AUTOSAR XML (schema 4-3-0)
package /ComponentTypes
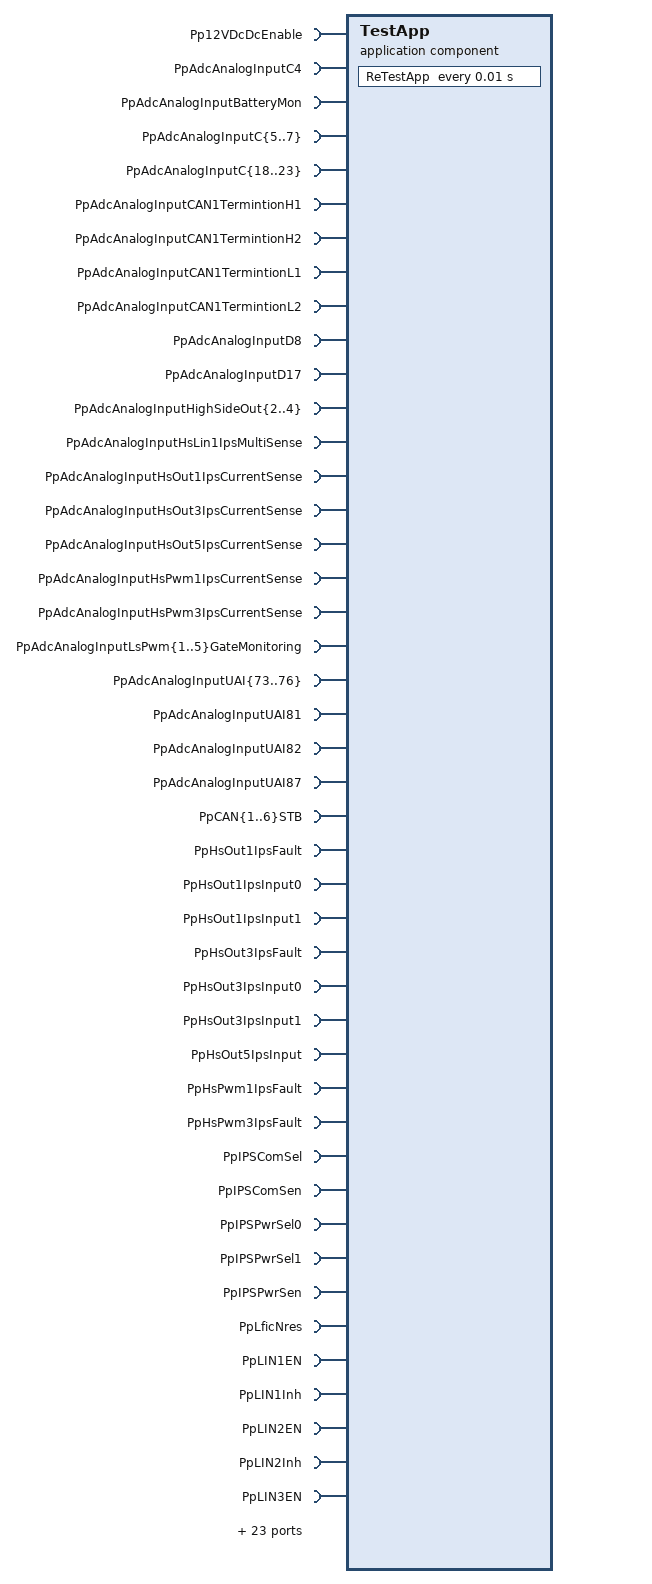
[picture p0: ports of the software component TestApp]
  application sw component type TestApp
    92 x require port:
      Pp12VDcDcEnable: required-com-specs=[]
      PpAdcAnalogInputC4
      PpAdcAnalogInputBatteryMon
      PpAdcAnalogInputC{5..7}
      PpAdcAnalogInputC{18..23}
      PpAdcAnalogInputCAN1TermintionH1
      PpAdcAnalogInputCAN1TermintionH2
      PpAdcAnalogInputCAN1TermintionL1
      PpAdcAnalogInputCAN1TermintionL2
      PpAdcAnalogInputD8
      PpAdcAnalogInputD17
      PpAdcAnalogInputHighSideOut{2..4}
      PpAdcAnalogInputHsLin1IpsMultiSense
      PpAdcAnalogInputHsOut1IpsCurrentSense
      PpAdcAnalogInputHsOut3IpsCurrentSense
      PpAdcAnalogInputHsOut5IpsCurrentSense
      PpAdcAnalogInputHsPwm1IpsCurrentSense
      PpAdcAnalogInputHsPwm3IpsCurrentSense
      PpAdcAnalogInputLsPwm{1..5}GateMonitoring
      PpAdcAnalogInputUAI{73..76}
      PpAdcAnalogInputUAI81
      PpAdcAnalogInputUAI82
      PpAdcAnalogInputUAI87
      PpCAN{1..6}STB: required-com-specs=[]
      PpHsOut1IpsFault: required-com-specs=[]
      PpHsOut1IpsInput0: required-com-specs=[]
      PpHsOut1IpsInput1: required-com-specs=[]
      PpHsOut3IpsFault: required-com-specs=[]
      PpHsOut3IpsInput0: required-com-specs=[]
      PpHsOut3IpsInput1: required-com-specs=[]
      PpHsOut5IpsInput: required-com-specs=[]
      PpHsPwm1IpsFault: required-com-specs=[]
      PpHsPwm3IpsFault: required-com-specs=[]
      PpIPSComSel: required-com-specs=[]
      PpIPSComSen: required-com-specs=[]
      PpIPSPwrSel0: required-com-specs=[]
      PpIPSPwrSel1: required-com-specs=[]
      PpIPSPwrSen: required-com-specs=[]
      PpLficNres: required-com-specs=[]
      PpLIN1EN: required-com-specs=[]
      PpLIN1Inh: required-com-specs=[]
      PpLIN2EN: required-com-specs=[]
      PpLIN2Inh: required-com-specs=[]
      PpLIN3EN: required-com-specs=[]
      PpLIN3Inh: required-com-specs=[]
      PpLIN4EN: required-com-specs=[]
      PpLIN4Inh: required-com-specs=[]
      PpLIN5EN: required-com-specs=[]
      PpLIN5Inh: required-com-specs=[]
      PpLIN6EN: required-com-specs=[]
      PpLIN6Inh: required-com-specs=[]
      PpLINPwrIpsFaultRst: required-com-specs=[]
      PpLINPwrIpsIn0: required-com-specs=[]
      PpLINPwrIpsIn1: required-com-specs=[]
      PpLINSecurityEN: required-com-specs=[]
      PpLINSecurityInh: required-com-specs=[]
      PpLivingPopUpCtrl: required-com-specs=[]
      PpParkedPopUpCtrl: required-com-specs=[]
      PpPwmHsPwm1IpsIn0
      PpPwmHsPwm1IpsIn1
      PpPwmHsPwm3IpsIn0
      PpPwmHsPwm3IpsIn1
      PpPwmLsPwm{1..5}Gate
      PpPwmRegWdtOut
      PpRegRst: required-com-specs=[]
      PpRficNres: required-com-specs=[]
      PpRficRed: required-com-specs=[]
    behavior TestApp_InternalBehavior
      timing event TMT_ReTestApp: start-on-event=ReTestApp, period=0.01
      runnable ReTestApp
        136 x sync call:
          SC_Pp12VDcDcEnable_DioRead: operation=Pp12VDcDcEnable
          SC_Pp12VDcDcEnable_DioWrite: operation=Pp12VDcDcEnable
          SC_PpAdcAnalogInputBatteryMon_AdcRead: operation=PpAdcAnalogInputBatteryMon
          SC_PpAdcAnalogInputC{18..23}_AdcRead: operation=PpAdcAnalogInputC{18..23}
          SC_PpAdcAnalogInputC{4..7}_AdcRead: operation=PpAdcAnalogInputC{4..7}
          SC_PpAdcAnalogInputCAN1TermintionH1_AdcRead: operation=PpAdcAnalogInputCAN1TermintionH1
          SC_PpAdcAnalogInputCAN1TermintionH2_AdcRead: operation=PpAdcAnalogInputCAN1TermintionH2
          SC_PpAdcAnalogInputCAN1TermintionL1_AdcRead: operation=PpAdcAnalogInputCAN1TermintionL1
          SC_PpAdcAnalogInputCAN1TermintionL2_AdcRead: operation=PpAdcAnalogInputCAN1TermintionL2
          SC_PpAdcAnalogInputD17_AdcRead: operation=PpAdcAnalogInputD17
          SC_PpAdcAnalogInputD8_AdcRead: operation=PpAdcAnalogInputD8
          SC_PpAdcAnalogInputHighSideOut{2..4}_AdcRead: operation=PpAdcAnalogInputHighSideOut{2..4}
          SC_PpAdcAnalogInputHsLin1IpsMultiSense_AdcRead: operation=PpAdcAnalogInputHsLin1IpsMultiSense
          SC_PpAdcAnalogInputHsOut1IpsCurrentSense_AdcRead: operation=PpAdcAnalogInputHsOut1IpsCurrentSense
          SC_PpAdcAnalogInputHsOut3IpsCurrentSense_AdcRead: operation=PpAdcAnalogInputHsOut3IpsCurrentSense
          SC_PpAdcAnalogInputHsOut5IpsCurrentSense_AdcRead: operation=PpAdcAnalogInputHsOut5IpsCurrentSense
          SC_PpAdcAnalogInputHsPwm1IpsCurrentSense_AdcRead: operation=PpAdcAnalogInputHsPwm1IpsCurrentSense
          SC_PpAdcAnalogInputHsPwm3IpsCurrentSense_AdcRead: operation=PpAdcAnalogInputHsPwm3IpsCurrentSense
          SC_PpAdcAnalogInputLsPwm{1..5}GateMonitoring_AdcRead: operation=PpAdcAnalogInputLsPwm{1..5}GateMonitoring
          SC_PpAdcAnalogInputUAI{73..76}_AdcRead: operation=PpAdcAnalogInputUAI{73..76}
          SC_PpAdcAnalogInputUAI81_AdcRead: operation=PpAdcAnalogInputUAI81
          SC_PpAdcAnalogInputUAI82_AdcRead: operation=PpAdcAnalogInputUAI82
          SC_PpAdcAnalogInputUAI87_AdcRead: operation=PpAdcAnalogInputUAI87
          SC_PpCAN1STB_DioRead: operation=PpCAN1STB
          SC_PpCAN1STB_DioWrite: operation=PpCAN1STB
          SC_PpCAN2STB_DioRead: operation=PpCAN2STB
          SC_PpCAN2STB_DioWrite: operation=PpCAN2STB
          SC_PpCAN3STB_DioRead: operation=PpCAN3STB
          SC_PpCAN3STB_DioWrite: operation=PpCAN3STB
          SC_PpCAN4STB_DioRead: operation=PpCAN4STB
          SC_PpCAN4STB_DioWrite: operation=PpCAN4STB
          SC_PpCAN5STB_DioRead: operation=PpCAN5STB
          SC_PpCAN5STB_DioWrite: operation=PpCAN5STB
          SC_PpCAN6STB_DioRead: operation=PpCAN6STB
          SC_PpCAN6STB_DioWrite: operation=PpCAN6STB
          SC_PpHsOut1IpsFault_DioRead: operation=PpHsOut1IpsFault
          SC_PpHsOut1IpsFault_DioWrite: operation=PpHsOut1IpsFault
          SC_PpHsOut1IpsInput0_DioRead: operation=PpHsOut1IpsInput0
          SC_PpHsOut1IpsInput0_DioWrite: operation=PpHsOut1IpsInput0
          SC_PpHsOut1IpsInput1_DioRead: operation=PpHsOut1IpsInput1
          SC_PpHsOut1IpsInput1_DioWrite: operation=PpHsOut1IpsInput1
          SC_PpHsOut3IpsFault_DioRead: operation=PpHsOut3IpsFault
          SC_PpHsOut3IpsFault_DioWrite: operation=PpHsOut3IpsFault
          SC_PpHsOut3IpsInput0_DioRead: operation=PpHsOut3IpsInput0
          SC_PpHsOut3IpsInput0_DioWrite: operation=PpHsOut3IpsInput0
          SC_PpHsOut3IpsInput1_DioRead: operation=PpHsOut3IpsInput1
          SC_PpHsOut3IpsInput1_DioWrite: operation=PpHsOut3IpsInput1
          SC_PpHsOut5IpsInput_DioRead: operation=PpHsOut5IpsInput
          SC_PpHsOut5IpsInput_DioWrite: operation=PpHsOut5IpsInput
          SC_PpHsPwm1IpsFault_DioRead: operation=PpHsPwm1IpsFault
          SC_PpHsPwm1IpsFault_DioWrite: operation=PpHsPwm1IpsFault
          SC_PpHsPwm3IpsFault_DioRead: operation=PpHsPwm3IpsFault
          SC_PpHsPwm3IpsFault_DioWrite: operation=PpHsPwm3IpsFault
          SC_PpIPSComSel_DioRead: operation=PpIPSComSel
          SC_PpIPSComSel_DioWrite: operation=PpIPSComSel
          SC_PpIPSComSen_DioRead: operation=PpIPSComSen
          SC_PpIPSComSen_DioWrite: operation=PpIPSComSen
          SC_PpIPSPwrSel0_DioRead: operation=PpIPSPwrSel0
          SC_PpIPSPwrSel0_DioWrite: operation=PpIPSPwrSel0
          SC_PpIPSPwrSel1_DioRead: operation=PpIPSPwrSel1
          SC_PpIPSPwrSel1_DioWrite: operation=PpIPSPwrSel1
          SC_PpIPSPwrSen_DioRead: operation=PpIPSPwrSen
          SC_PpIPSPwrSen_DioWrite: operation=PpIPSPwrSen
          SC_PpLIN1EN_DioRead: operation=PpLIN1EN
          SC_PpLIN1EN_DioWrite: operation=PpLIN1EN
          SC_PpLIN1Inh_DioRead: operation=PpLIN1Inh
          SC_PpLIN1Inh_DioWrite: operation=PpLIN1Inh
          SC_PpLIN2EN_DioRead: operation=PpLIN2EN
          SC_PpLIN2EN_DioWrite: operation=PpLIN2EN
          SC_PpLIN2Inh_DioRead: operation=PpLIN2Inh
          SC_PpLIN2Inh_DioWrite: operation=PpLIN2Inh
          SC_PpLIN3EN_DioRead: operation=PpLIN3EN
          SC_PpLIN3EN_DioWrite: operation=PpLIN3EN
          SC_PpLIN3Inh_DioRead: operation=PpLIN3Inh
          SC_PpLIN3Inh_DioWrite: operation=PpLIN3Inh
          SC_PpLIN4EN_DioRead: operation=PpLIN4EN
          SC_PpLIN4EN_DioWrite: operation=PpLIN4EN
          SC_PpLIN4Inh_DioRead: operation=PpLIN4Inh
          SC_PpLIN4Inh_DioWrite: operation=PpLIN4Inh
          SC_PpLIN5EN_DioRead: operation=PpLIN5EN
          SC_PpLIN5EN_DioWrite: operation=PpLIN5EN
          SC_PpLIN5Inh_DioRead: operation=PpLIN5Inh
          SC_PpLIN5Inh_DioWrite: operation=PpLIN5Inh
          SC_PpLIN6EN_DioRead: operation=PpLIN6EN
          SC_PpLIN6EN_DioWrite: operation=PpLIN6EN
          SC_PpLIN6Inh_DioRead: operation=PpLIN6Inh
          SC_PpLIN6Inh_DioWrite: operation=PpLIN6Inh
          SC_PpLINPwrIpsFaultRst_DioRead: operation=PpLINPwrIpsFaultRst
          SC_PpLINPwrIpsFaultRst_DioWrite: operation=PpLINPwrIpsFaultRst
          SC_PpLINPwrIpsIn0_DioRead: operation=PpLINPwrIpsIn0
          SC_PpLINPwrIpsIn0_DioWrite: operation=PpLINPwrIpsIn0
          SC_PpLINPwrIpsIn1_DioRead: operation=PpLINPwrIpsIn1
          SC_PpLINPwrIpsIn1_DioWrite: operation=PpLINPwrIpsIn1
          SC_PpLINSecurityEN_DioRead: operation=PpLINSecurityEN
          SC_PpLINSecurityEN_DioWrite: operation=PpLINSecurityEN
          SC_PpLINSecurityInh_DioRead: operation=PpLINSecurityInh
          SC_PpLINSecurityInh_DioWrite: operation=PpLINSecurityInh
          SC_PpLficNres_DioRead: operation=PpLficNres
          SC_PpLficNres_DioWrite: operation=PpLficNres
          SC_PpLivingPopUpCtrl_DioRead: operation=PpLivingPopUpCtrl
          SC_PpLivingPopUpCtrl_DioWrite: operation=PpLivingPopUpCtrl
          SC_PpParkedPopUpCtrl_DioRead: operation=PpParkedPopUpCtrl
          SC_PpParkedPopUpCtrl_DioWrite: operation=PpParkedPopUpCtrl
          SC_PpPwmHsPwm1IpsIn0_PwmDutySet: operation=PpPwmHsPwm1IpsIn0
          SC_PpPwmHsPwm1IpsIn1_PwmDutySet: operation=PpPwmHsPwm1IpsIn1
          SC_PpPwmHsPwm3IpsIn0_PwmDutySet: operation=PpPwmHsPwm3IpsIn0
          SC_PpPwmHsPwm3IpsIn1_PwmDutySet: operation=PpPwmHsPwm3IpsIn1
          SC_PpPwmLsPwm{1..5}Gate_PwmDutySet: operation=PpPwmLsPwm{1..5}Gate
          SC_PpPwmRegWdtOut_PwmDutySet: operation=PpPwmRegWdtOut
          SC_PpRegRst_DioRead: operation=PpRegRst
          SC_PpRegRst_DioWrite: operation=PpRegRst
          SC_PpRficNres_DioRead: operation=PpRficNres
          SC_PpRficNres_DioWrite: operation=PpRficNres
          SC_PpRficRed_DioRead: operation=PpRficRed
          SC_PpRficRed_DioWrite: operation=PpRficRed
  swc implementation TestApp_Implementation: behavior=TestApp_InternalBehavior
